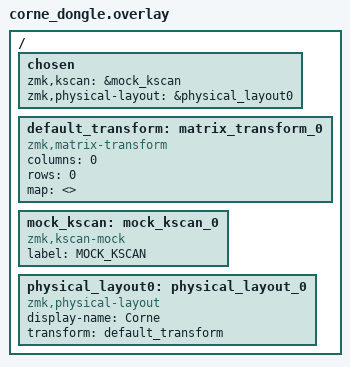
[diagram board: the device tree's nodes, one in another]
#include <dt-bindings/zmk/matrix_transform.h>

/ {
    chosen {
        zmk,kscan = &mock_kscan;
        zmk,physical-layout = &physical_layout0;
    };

    default_transform: matrix_transform_0 {
        compatible = "zmk,matrix-transform";
        columns = <0>;
        rows = <0>;
        map = <>;
    };

    mock_kscan: mock_kscan_0 {
        compatible = "zmk,kscan-mock";
        label = "MOCK_KSCAN";
    };

    physical_layout0: physical_layout_0 {
        compatible = "zmk,physical-layout";
        display-name = "Corne";
        // Now this line is valid because &default_transform exists
        transform = <&default_transform>;
    };
};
